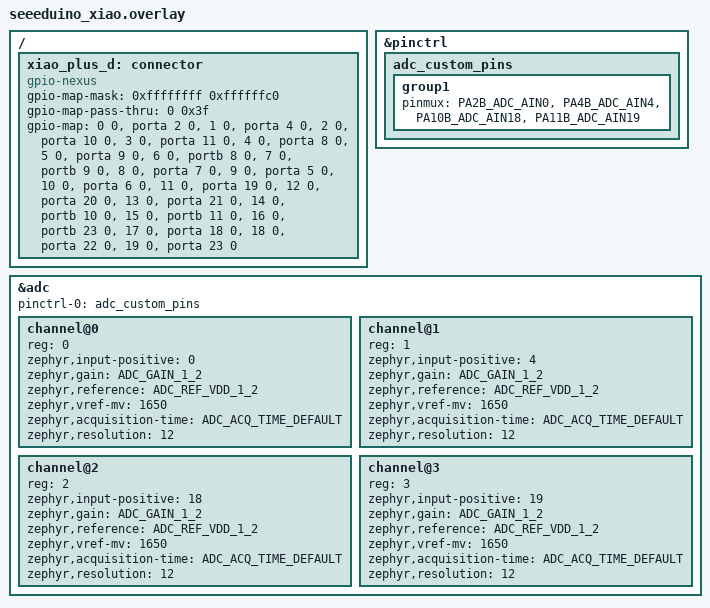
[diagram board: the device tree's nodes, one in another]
&pinctrl {
    adc_custom_pins: adc_custom_pins {
        group1 {
            /* D0, D1, D2, D3 */
            pinmux = <PA2B_ADC_AIN0>, <PA4B_ADC_AIN4>, <PA10B_ADC_AIN18>, <PA11B_ADC_AIN19>;
        };
    };
};

xiao_adc: &adc {
    pinctrl-0 = <&adc_custom_pins>;
    pinctrl-names = "default";

    status = "okay";
    #address-cells = <1>;
    #size-cells = <0>;

    channel@0 {
        reg = <0>; /* D0, PA02 */
        zephyr,input-positive = <0>; /* AIN0 */
        zephyr,gain = "ADC_GAIN_1_2";
        zephyr,reference = "ADC_REF_VDD_1_2";
        zephyr,vref-mv = <1650>; /* VDDANA/2, VDDANA assumed 3.3V */
        zephyr,acquisition-time = <ADC_ACQ_TIME_DEFAULT>;
        zephyr,resolution = <12>;
    };

    channel@1 {
        reg = <1>; /* D1, PA04 */
        zephyr,input-positive = <4>; /* AIN4 */
        zephyr,gain = "ADC_GAIN_1_2";
        zephyr,reference = "ADC_REF_VDD_1_2";
        zephyr,vref-mv = <1650>; /* VDDANA/2, VDDANA assumed 3.3V */
        zephyr,acquisition-time = <ADC_ACQ_TIME_DEFAULT>;
        zephyr,resolution = <12>;
    };

    channel@2 {
        reg = <2>; /* D2, PA10 */
        zephyr,input-positive = <18>; /* AIN18 */
        zephyr,gain = "ADC_GAIN_1_2";
        zephyr,reference = "ADC_REF_VDD_1_2";
        zephyr,vref-mv = <1650>; /* VDDANA/2, VDDANA assumed 3.3V */
        zephyr,acquisition-time = <ADC_ACQ_TIME_DEFAULT>;
        zephyr,resolution = <12>;
    };

    channel@3 {
        reg = <3>; /* D3, PA11 */
        zephyr,input-positive = <19>; /* AIN19 */
        zephyr,gain = "ADC_GAIN_1_2";
        zephyr,reference = "ADC_REF_VDD_1_2";
        zephyr,vref-mv = <1650>; /* VDDANA/2, VDDANA assumed 3.3V */
        zephyr,acquisition-time = <ADC_ACQ_TIME_DEFAULT>;
        zephyr,resolution = <12>;
    };
};

/ {
    xiao_plus_d: connector {
        compatible = "gpio-nexus";
        #gpio-cells = <2>;
        gpio-map-mask = <0xffffffff 0xffffffc0>;
        gpio-map-pass-thru = <0 0x3f>;
        gpio-map = <0 0 &porta 2 0>, /* D0 */
            <1 0 &porta 4 0>,        /* D1 */
            <2 0 &porta 10 0>,       /* D2 */
            <3 0 &porta 11 0>,       /* D3 */
            <4 0 &porta 8 0>,        /* D4 */
            <5 0 &porta 9 0>,        /* D5 */
            <6 0 &portb 8 0>,        /* D6 */
            <7 0 &portb 9 0>,        /* D7 */
            <8 0 &porta 7 0>,        /* D8 */
            <9 0 &porta 5 0>,        /* D9 */
            <10 0 &porta 6 0>,       /* D10 */
            <11 0 &porta 19 0>,      /* D0.5 */
            <12 0 &porta 20 0>,      /* D1.5 */
            <13 0 &porta 21 0>,      /* D2.5 */
            <14 0 &portb 10 0>,      /* D3.5 */
            <15 0 &portb 11 0>,      /* D4.5 */
            <16 0 &portb 23 0>,      /* D5.5 */
            <17 0 &porta 18 0>,      /* D7.5 */
            <18 0 &porta 22 0>,      /* D8.5 */
            <19 0 &porta 23 0>;      /* D9.5 */
    };
};
